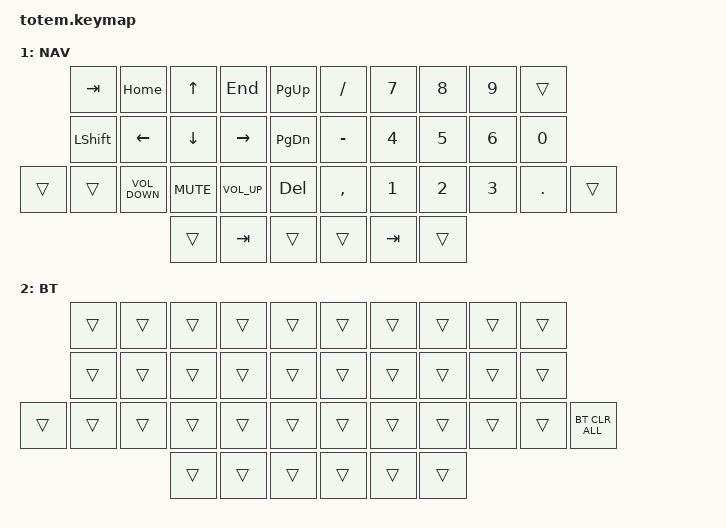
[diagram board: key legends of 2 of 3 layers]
#include <behaviors.dtsi>
#include <dt-bindings/zmk/bt.h>
#include <dt-bindings/zmk/keys.h>

#define BASE 0
#define NAV  1
#define SYM  2
#define NUM  3
#define FUN  4

&sk {
    quick-release;
    release-after-ms = <1600>;
};

/ {
    combos {
        compatible = "zmk,combos";

        combo_CAPSWORD {
            key-positions = <21 22>;
            bindings = <&caps_word>;
            layers = <0>;
        };
    };
};

/ {
    conditional_layers {
        compatible = "zmk,conditional-layers";

        num_layer {
            if-layers = <1 1>;
            then-layer = <1>;
        };
    };

    behaviors {
        appswap: appswap {
            compatible = "zmk,behavior-tri-state";
            #binding-cells = <0>;
            bindings = <&kt LGUI>, <&kp TAB>, <&kt LGUI>;
        };

        winswap: winswap {
            compatible = "zmk,behavior-tri-state";
            #binding-cells = <0>;
            bindings = <&kt LGUI>, <&kp GRAVE>, <&kt LGUI>;
        };

        tabswap: tabswap {
            compatible = "zmk,behavior-tri-state";
            #binding-cells = <0>;
            bindings = <&kt LCTRL>, <&kp TAB>, <&kt LCTRL>;
        };

        new_behavior_hold_tap: new_behavior_hold_tap {
            compatible = "zmk,behavior-hold-tap";
            label = "NEW_BEHAVIOR_HOLD_TAP";
            bindings = <&kp>, <&kp>;

            #binding-cells = <2>;
            tapping-term-ms = <250>;
            flavor = "tap-preferred";
        };
    };

    keymap {
        compatible = "zmk,keymap";

        // ▄▄▄▄▄▄▄▄▄▄▄▄▄▄▄▄▄▄▄▄▄▄▄▄▄▄▄▄▄▄▄▄▄▄▄▄▄▄▄▄▄▄▄▄▄▄▄▄▄▄▄▄▄▄▄▄▄▄▄▄▄▄▄▄▄▄▄▄▄▄▄▄▄▄▄▄▄▄▄▄▄▄▄▄▄▄▄▄▄▄▄▄▄▄▄▄▄▄▄▄▄▄▄▄▄▄▄▄▄▄▄▄▄▄▄▄▄▄▄▄▄▄▄▄▄▄▄▄▄▄▄▄▄▄▄▄▄▄▄▄▄▄▄▄▄▄▄▄▄

        BASE {
            display-name = "BASE";

            // ┏━━━━━━━━━━━━━━━━━━━━━━━━━━━━━━━━━━━━━━━┓
            // ┃          0 - Base                     ┃
            // ┗━━━━━━━━━━━━━━━━━━━━━━━━━━━━━━━━━━━━━━━┛
            //             ┏━━━━━━━━━━━┳━━━━━━━━━━━┳━━━━━━━━━━━┳━━━━━━━━━━━┳━━━━━━━━━━━┓   ┏━━━━━━━━━━━┳━━━━━━━━━━━┳━━━━━━━━━━━┳━━━━━━━━━━━┳━━━━━━━━━━━┓
            //             ┃     Q     ┃     W     ┃     F     ┃     P     ┃     B     ┃   ┃     J     ┃     L     ┃     U     ┃     Y     ┃     '     ┃
            //             ┣━━━━━━━━━━━╋━━━━━━━━━━━╋━━━━━━━━━━━╋━━━━━━━━━━━╋━━━━━━━━━━━┫   ┣━━━━━━━━━━━╋━━━━━━━━━━━╋━━━━━━━━━━━╋━━━━━━━━━━━╋━━━━━━━━━━━┫
            //             ┃     A     ┃     R     ┃     S     ┃     T     ┃     G     ┃   ┃     M     ┃     N     ┃     E     ┃     I     ┃     O     ┃
            // ┏━━━━━━━━━━━╋━━━━━━━━━━━╋━━━━━━━━━━━╋━━━━━━━━━━━╋━━━━━━━━━━━╋━━━━━━━━━━━┫   ┣━━━━━━━━━━━╋━━━━━━━━━━━╋━━━━━━━━━━━╋━━━━━━━━━━━╋━━━━━━━━━━━╋━━━━━━━━━━━┓
            // ┃    ESC    ┃     Z     ┃     X     ┃     C     ┃     D     ┃     V     ┃   ┃     K     ┃     H     ┃     ,     ┃     .     ┃     /     ┃    BSPC   ┃
            // ┗━━━━━━━━━━━┻━━━━━━━━━━━┻━━━━━━━━━━━╋━━━━━━━━━━━╋━━━━━━━━━━━╋━━━━━━━━━━━┫   ┣━━━━━━━━━━━╋━━━━━━━━━━━╋━━━━━━━━━━━┫━━━━━━━━━━━┻━━━━━━━━━━━┻━━━━━━━━━━━┛
            //                                     ┃    NAV    ┃   SHIFT   ┃    FUN    ┃   ┃           ┃   SPACE   ┃    SYM    ┃
            //                                     ┗━━━━━━━━━━━┻━━━━━━━━━━━┻━━━━━━━━━━━┛   ┗━━━━━━━━━━━┻━━━━━━━━━━━┻━━━━━━━━━━━┛

            bindings = <
              &kp Q  &kp W                              &kp E                              &kp R                           &kp T              &kp Y        &kp U                                   &kp I                              &kp O                              &kp P
              &kp A  &new_behavior_hold_tap LEFT_ALT S  &new_behavior_hold_tap LEFT_GUI D  &new_behavior_hold_tap LCTRL F  &kp G              &kp H        &new_behavior_hold_tap LCTRL J          &new_behavior_hold_tap LEFT_GUI K  &new_behavior_hold_tap LEFT_ALT L  &kp SEMI
&lt 2 ESCAPE  &kp Z  &kp X                              &kp C                              &kp V                           &kp B              &kp N        &kp M                                   &kp COMMA                          &kp DOT                            &kp FSLH  &kp BSPC
                                                        &none                              &kp LSHFT                       &lt 1 BACKSPACE    &lt 1 SPACE  &new_behavior_hold_tap RIGHT_ALT ENTER
            >;
        };

        // ▄▄▄▄▄▄▄▄▄▄▄▄▄▄▄▄▄▄▄▄▄▄▄▄▄▄▄▄▄▄▄▄▄▄▄▄▄▄▄▄▄▄▄▄▄▄▄▄▄▄▄▄▄▄▄▄▄▄▄▄▄▄▄▄▄▄▄▄▄▄▄▄▄▄▄▄▄▄▄▄▄▄▄▄▄▄▄▄▄▄▄▄▄▄▄▄▄▄▄▄▄▄▄▄▄▄▄▄▄▄▄▄▄▄▄▄▄▄▄▄▄▄▄▄▄▄▄▄▄▄▄▄▄▄▄▄▄▄▄▄▄▄▄▄▄▄▄▄▄
        // ▄▄▄▄▄▄▄▄▄▄▄▄▄▄▄▄▄▄▄▄▄▄▄▄▄▄▄▄▄▄▄▄▄▄▄▄▄▄▄▄▄▄▄▄▄▄▄▄▄▄▄▄▄▄▄▄▄▄▄▄▄▄▄▄▄▄▄▄▄▄▄▄▄▄▄▄▄▄▄▄▄▄▄▄▄▄▄▄▄▄▄▄▄▄▄▄▄▄▄▄▄▄▄▄▄▄▄▄▄▄▄▄▄▄▄▄▄▄▄▄▄▄▄▄▄▄▄▄▄▄▄▄▄▄▄▄▄▄▄▄▄▄▄▄▄▄▄▄▄
        // ▄▄▄▄▄▄▄▄▄▄▄▄▄▄▄▄▄▄▄▄▄▄▄▄▄▄▄▄▄▄▄▄▄▄▄▄▄▄▄▄▄▄▄▄▄▄▄▄▄▄▄▄▄▄▄▄▄▄▄▄▄▄▄▄▄▄▄▄▄▄▄▄▄▄▄▄▄▄▄▄▄▄▄▄▄▄▄▄▄▄▄▄▄▄▄▄▄▄▄▄▄▄▄▄▄▄▄▄▄▄▄▄▄▄▄▄▄▄▄▄▄▄▄▄▄▄▄▄▄▄▄▄▄▄▄▄▄▄▄▄▄▄▄▄▄▄▄▄▄
        // ▄▄▄▄▄▄▄▄▄▄▄▄▄▄▄▄▄▄▄▄▄▄▄▄▄▄▄▄▄▄▄▄▄▄▄▄▄▄▄▄▄▄▄▄▄▄▄▄▄▄▄▄▄▄▄▄▄▄▄▄▄▄▄▄▄▄▄▄▄▄▄▄▄▄▄▄▄▄▄▄▄▄▄▄▄▄▄▄▄▄▄▄▄▄▄▄▄▄▄▄▄▄▄▄▄▄▄▄▄▄▄▄▄▄▄▄▄▄▄▄▄▄▄▄▄▄▄▄▄▄▄▄▄▄▄▄▄▄▄▄▄▄▄▄▄▄▄▄▄

        NAV {
            bindings = <
        &kp TAB    &kp HOME           &kp UP      &kp END          &kp PG_UP    &kp FSLH   &kp N7   &kp N8  &kp N9  &trans
        &kp LSHFT  &kp LEFT           &kp DOWN    &kp RIGHT        &kp PG_DN    &kp MINUS  &kp N4   &kp N5  &kp N6  &kp N0
&trans  &trans     &kp C_VOLUME_DOWN  &kp K_MUTE  &kp C_VOLUME_UP  &kp DEL      &kp COMMA  &kp N1   &kp N2  &kp N3  &kp DOT  &trans
                                      &trans      &kp TAB          &trans       &trans     &kp TAB  &trans
            >;
        };

        BT {
            bindings = <
        &trans  &trans  &trans  &trans  &trans    &trans  &trans  &trans  &trans  &trans
        &trans  &trans  &trans  &trans  &trans    &trans  &trans  &trans  &trans  &trans
&trans  &trans  &trans  &trans  &trans  &trans    &trans  &trans  &trans  &trans  &trans  &bt BT_CLR_ALL
                        &trans  &trans  &trans    &trans  &trans  &trans
            >;
        };

        // ▄▄▄▄▄▄▄▄▄▄▄▄▄▄▄▄▄▄▄▄▄▄▄▄▄▄▄▄▄▄▄▄▄▄▄▄▄▄▄▄▄▄▄▄▄▄▄▄▄▄▄▄▄▄▄▄▄▄▄▄▄▄▄▄▄▄▄▄▄▄▄▄▄▄▄▄▄▄▄▄▄▄▄▄▄▄▄▄▄▄▄▄▄▄▄▄▄▄▄▄▄▄▄▄▄▄▄▄▄▄▄▄▄▄▄▄▄▄▄▄▄▄▄▄▄▄▄▄▄▄▄▄▄▄▄▄▄▄▄▄▄▄▄▄▄▄▄▄▄
    };
};
